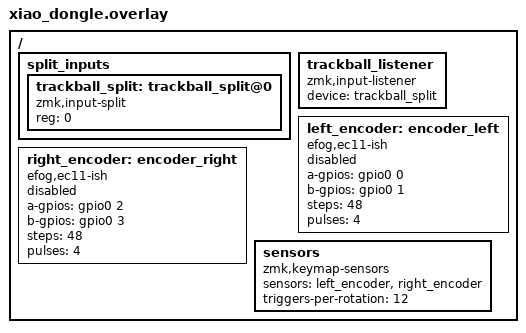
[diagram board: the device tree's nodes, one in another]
/* Dongle: trackball input-split proxy, listener, and sensor forwarding */

/ {
    split_inputs {
        #address-cells = <1>;
        #size-cells = <0>;

        trackball_split: trackball_split@0 {
            compatible = "zmk,input-split";
            reg = <0>;
        };
    };

    trackball_listener: trackball_listener {
        compatible = "zmk,input-listener";
        device = <&trackball_split>;
    };

    /* Dummy encoder nodes for sensor forwarding from trackball peripheral.
     * Disabled — no driver init. Needed so zmk,keymap-sensors phandles resolve. */
    left_encoder: encoder_left {
        compatible = "efog,ec11-ish";
        a-gpios = <&gpio0 0 0>;
        b-gpios = <&gpio0 1 0>;
        steps = <48>;
        pulses = <4>;
        status = "disabled";
    };

    right_encoder: encoder_right {
        compatible = "efog,ec11-ish";
        a-gpios = <&gpio0 2 0>;
        b-gpios = <&gpio0 3 0>;
        steps = <48>;
        pulses = <4>;
        status = "disabled";
    };

    sensors: sensors {
        compatible = "zmk,keymap-sensors";
        sensors = <&left_encoder &right_encoder>;
        triggers-per-rotation = <12>;
    };
};
